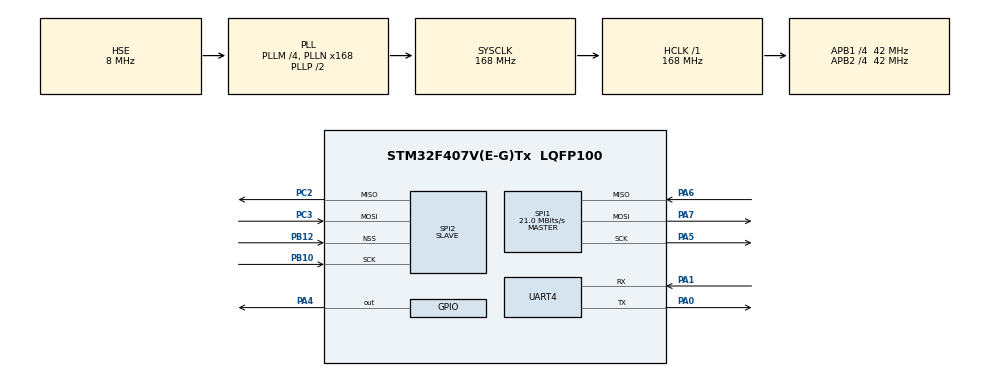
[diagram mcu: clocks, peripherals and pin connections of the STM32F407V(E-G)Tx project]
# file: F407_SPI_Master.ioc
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Mcu.Family=STM32F4
Dma.UART4_RX.0.MemInc=DMA_MINC_ENABLE
PC3.Mode=Full_Duplex_Slave
RCC.PLLSourceVirtual=RCC_PLLSOURCE_HSE
PA6.Mode=Full_Duplex_Master
PH0-OSC_IN.Signal=RCC_OSC_IN
SPI2.VirtualNSS=VM_NSSHARD
Dma.SPI2_RX.1.MemDataAlignment=DMA_MDATAALIGN_BYTE
RCC.CortexFreq_Value=168000000
PA7.Mode=Full_Duplex_Master
SPI1.VirtualType=VM_MASTER
SPI2.VirtualType=VM_SLAVE
PB10.Mode=Full_Duplex_Slave
NVIC.DMA1_Stream2_IRQn=true\:0\:0\:false\:false\:true\:false\:true
Dma.UART4_RX.0.Mode=DMA_CIRCULAR
PC2.Signal=SPI2_MISO
PC2.Mode=Full_Duplex_Slave
RCC.APB1CLKDivider=RCC_HCLK_DIV4
UART4.VirtualMode=Asynchronous
Dma.SPI2_RX.1.Mode=DMA_CIRCULAR
Dma.SPI2_RX.1.Direction=DMA_PERIPH_TO_MEMORY
RCC.SYSCLKSource=RCC_SYSCLKSOURCE_PLLCLK
ProjectManager.StackSize=0x400
PA0-WKUP.Signal=UART4_TX
PA0-WKUP.Mode=Asynchronous
Dma.SPI2_RX.1.PeriphDataAlignment=DMA_PDATAALIGN_BYTE
Dma.UART4_RX.0.Direction=DMA_PERIPH_TO_MEMORY
PA4.PinState=GPIO_PIN_SET
ProjectManager.TargetToolchain=STM32CubeIDE
SPI1.Direction=SPI_DIRECTION_2LINES
RCC.HCLKFreq_Value=168000000
RCC.APB2TimFreq_Value=84000000
SPI1.CalculateBaudRate=21.0 MBits/s
PC3.Signal=SPI2_MOSI
Dma.UART4_RX.0.PeriphInc=DMA_PINC_DISABLE
RCC.LSE_VALUE=32768
PA1.Signal=UART4_RX
RCC.AHBFreq_Value=168000000
PH0-OSC_IN.Mode=HSE-External-Oscillator
PB10.Signal=SPI2_SCK
PA5.Signal=SPI1_SCK
RCC.HSE_VALUE=8000000
board=custom
RCC.VCOOutputFreq_Value=336000000
Dma.UART4_RX.0.MemDataAlignment=DMA_MDATAALIGN_BYTE
Dma.UART4_RX.0.FIFOMode=DMA_FIFOMODE_DISABLE
PA4.GPIO_Speed=GPIO_SPEED_FREQ_VERY_HIGH
Dma.UART4_RX.0.Priority=DMA_PRIORITY_LOW
NVIC.SPI1_IRQn=true\:0\:0\:false\:false\:true\:true\:true
RCC.APB2Freq_Value=42000000
PA1.Mode=Asynchronous
Dma.SPI2_RX.1.FIFOMode=DMA_FIFOMODE_DISABLE
Dma.SPI2_RX.1.Priority=DMA_PRIORITY_LOW
SPI1.Mode=SPI_MODE_MASTER
PH1-OSC_OUT.Signal=RCC_OSC_OUT
NVIC.SPI2_IRQn=true\:0\:0\:false\:false\:true\:true\:true
Dma.UART4_RX.0.PeriphDataAlignment=DMA_PDATAALIGN_BYTE
Mcu.Name=STM32F407V(E-G)Tx
Dma.SPI2_RX.1.PeriphInc=DMA_PINC_DISABLE
PH1-OSC_OUT.Mode=HSE-External-Oscillator
RCC.48MHZClocksFreq_Value=84000000
PA4.Signal=GPIO_Output
RCC.SYSCLKFreq_VALUE=168000000
Mcu.Package=LQFP100
PA6.Signal=SPI1_MISO
PB12.Mode=NSS_Signal_Hard_Input
SPI2.Mode=SPI_MODE_SLAVE
ProjectManager.HeapSize=0x200
Dma.SPI2_RX.1.Instance=DMA1_Stream3
RCC.HSI_VALUE=16000000
NVIC.PriorityGroup=NVIC_PRIORITYGROUP_4
RCC.APB2CLKDivider=RCC_HCLK_DIV4
RCC.PLLM=4
RCC.PLLN=168
Dma.UART4_RX.0.Instance=DMA1_Stream2
Dma.Request1=SPI2_RX
RCC.APB1TimFreq_Value=84000000
NVIC.DMA1_Stream3_IRQn=true\:0\:0\:false\:false\:true\:false\:true
SPI2.Direction=SPI_DIRECTION_2LINES
Dma.Request0=UART4_RX
RCC.APB1Freq_Value=42000000
Dma.SPI2_RX.1.MemInc=DMA_MINC_ENABLE
PB12.Signal=SPI2_NSS
NVIC.UART4_IRQn=true\:0\:0\:false\:false\:true\:true\:true
PA5.Mode=Full_Duplex_Master
PA7.Signal=SPI1_MOSI

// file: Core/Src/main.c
/* USER CODE BEGIN Header */
/**
  ******************************************************************************
  * @file           : main.c
  * @brief          : Main program body
  ******************************************************************************
  * @attention
  *
  * <h2><center>&copy; Copyright (c) 2021 STMicroelectronics.
  * All rights reserved.</center></h2>
  *
  * This software component is licensed by ST under BSD 3-Clause license,
  * the "License"; You may not use this file except in compliance with the
  * License. You may obtain a copy of the License at:
  *                        opensource.org/licenses/BSD-3-Clause
  *
  ******************************************************************************
  */
/* USER CODE END Header */
#include "main.h"
#include <stdio.h>
#include <string.h>

/* USER CODE BEGIN PTD */
#define spi_enable  		HAL_GPIO_WritePin(GPIOA, GPIO_PIN_4, GPIO_PIN_RESET);
#define spi_disable 		HAL_GPIO_WritePin(GPIOA, GPIO_PIN_4, GPIO_PIN_SET);
/* USER CODE END PTD */

SPI_HandleTypeDef hspi1;
SPI_HandleTypeDef hspi2;
DMA_HandleTypeDef hdma_spi2_rx;

UART_HandleTypeDef huart4;
DMA_HandleTypeDef hdma_uart4_rx;

/* USER CODE BEGIN PV */
uint8_t receive_data, send_data;
/* USER CODE END PV */

void SystemClock_Config(void);
static void MX_GPIO_Init(void);
static void MX_DMA_Init(void);
static void MX_UART4_Init(void);
static void MX_SPI1_Init(void);
static void MX_SPI2_Init(void);
/* USER CODE BEGIN PFP */
int __io_putchar (int ch) {
	uint8_t c = ch;
	HAL_UART_Transmit(&huart4, &c, 1, HAL_MAX_DELAY);
	return ch;
}
/* USER CODE END PFP */

int main(void)
{

  /* MCU Configuration--------------------------------------------------------*/

  /* Reset of all peripherals, Initializes the Flash interface and the Systick. */
  HAL_Init();

  /* Configure the system clock */
  SystemClock_Config();

  /* Initialize all configured peripherals */
  MX_GPIO_Init();
  MX_DMA_Init();
  MX_UART4_Init();
  MX_SPI1_Init();
  MX_SPI2_Init();
  /* USER CODE BEGIN 2 */
  //HAL_SPI_Receive_DMA(&hspi2, &receive_data, 1);
  /* USER CODE END 2 */

  /* Infinite loop */
  while (1)
  {
		printf("=====Tran Minh Tan=====\r\n");
		spi_enable;
		HAL_SPI_TransmitReceive_IT(&hspi1, &send_data, &receive_data, 1);
		HAL_Delay(1000);
		send_data++;
  }
}

void HAL_SPI_TxCpltCallback(SPI_HandleTypeDef *hspi)
{
	if(hspi->Instance == hspi1.Instance)
	{
		spi_disable;
	}
}
void SystemClock_Config(void)
{
  RCC_OscInitTypeDef RCC_OscInitStruct = {0};
  RCC_ClkInitTypeDef RCC_ClkInitStruct = {0};

  /** Configure the main internal regulator output voltage
  */
  __HAL_RCC_PWR_CLK_ENABLE();
  __HAL_PWR_VOLTAGESCALING_CONFIG(PWR_REGULATOR_VOLTAGE_SCALE1);
  /** Initializes the RCC Oscillators according to the specified parameters
  * in the RCC_OscInitTypeDef structure.
  */
  RCC_OscInitStruct.OscillatorType = RCC_OSCILLATORTYPE_HSE;
  RCC_OscInitStruct.HSEState = RCC_HSE_ON;
  RCC_OscInitStruct.PLL.PLLState = RCC_PLL_ON;
  RCC_OscInitStruct.PLL.PLLSource = RCC_PLLSOURCE_HSE;
  RCC_OscInitStruct.PLL.PLLM = 4;
  RCC_OscInitStruct.PLL.PLLN = 168;
  RCC_OscInitStruct.PLL.PLLP = RCC_PLLP_DIV2;
  RCC_OscInitStruct.PLL.PLLQ = 4;
  if (HAL_RCC_OscConfig(&RCC_OscInitStruct) != HAL_OK)
  {
    Error_Handler();
  }
  /** Initializes the CPU, AHB and APB buses clocks
  */
  RCC_ClkInitStruct.ClockType = RCC_CLOCKTYPE_HCLK|RCC_CLOCKTYPE_SYSCLK
                              |RCC_CLOCKTYPE_PCLK1|RCC_CLOCKTYPE_PCLK2;
  RCC_ClkInitStruct.SYSCLKSource = RCC_SYSCLKSOURCE_PLLCLK;
  RCC_ClkInitStruct.AHBCLKDivider = RCC_SYSCLK_DIV1;
  RCC_ClkInitStruct.APB1CLKDivider = RCC_HCLK_DIV4;
  RCC_ClkInitStruct.APB2CLKDivider = RCC_HCLK_DIV4;

  if (HAL_RCC_ClockConfig(&RCC_ClkInitStruct, FLASH_LATENCY_5) != HAL_OK)
  {
    Error_Handler();
  }
}

static void MX_SPI1_Init(void)
{

  /* SPI1 parameter configuration*/
  hspi1.Instance = SPI1;
  hspi1.Init.Mode = SPI_MODE_MASTER;
  hspi1.Init.Direction = SPI_DIRECTION_2LINES;
  hspi1.Init.DataSize = SPI_DATASIZE_8BIT;
  hspi1.Init.CLKPolarity = SPI_POLARITY_LOW;
  hspi1.Init.CLKPhase = SPI_PHASE_1EDGE;
  hspi1.Init.NSS = SPI_NSS_SOFT;
  hspi1.Init.BaudRatePrescaler = SPI_BAUDRATEPRESCALER_2;
  hspi1.Init.FirstBit = SPI_FIRSTBIT_MSB;
  hspi1.Init.TIMode = SPI_TIMODE_DISABLE;
  hspi1.Init.CRCCalculation = SPI_CRCCALCULATION_DISABLE;
  hspi1.Init.CRCPolynomial = 10;
  if (HAL_SPI_Init(&hspi1) != HAL_OK)
  {
    Error_Handler();
  }

}

static void MX_SPI2_Init(void)
{

  /* SPI2 parameter configuration*/
  hspi2.Instance = SPI2;
  hspi2.Init.Mode = SPI_MODE_SLAVE;
  hspi2.Init.Direction = SPI_DIRECTION_2LINES;
  hspi2.Init.DataSize = SPI_DATASIZE_8BIT;
  hspi2.Init.CLKPolarity = SPI_POLARITY_LOW;
  hspi2.Init.CLKPhase = SPI_PHASE_1EDGE;
  hspi2.Init.NSS = SPI_NSS_HARD_INPUT;
  hspi2.Init.FirstBit = SPI_FIRSTBIT_MSB;
  hspi2.Init.TIMode = SPI_TIMODE_DISABLE;
  hspi2.Init.CRCCalculation = SPI_CRCCALCULATION_DISABLE;
  hspi2.Init.CRCPolynomial = 10;
  if (HAL_SPI_Init(&hspi2) != HAL_OK)
  {
    Error_Handler();
  }

}

static void MX_UART4_Init(void)
{

  huart4.Instance = UART4;
  huart4.Init.BaudRate = 115200;
  huart4.Init.WordLength = UART_WORDLENGTH_8B;
  huart4.Init.StopBits = UART_STOPBITS_1;
  huart4.Init.Parity = UART_PARITY_NONE;
  huart4.Init.Mode = UART_MODE_TX_RX;
  huart4.Init.HwFlowCtl = UART_HWCONTROL_NONE;
  huart4.Init.OverSampling = UART_OVERSAMPLING_16;
  if (HAL_UART_Init(&huart4) != HAL_OK)
  {
    Error_Handler();
  }

}

static void MX_DMA_Init(void)
{

  /* DMA controller clock enable */
  __HAL_RCC_DMA1_CLK_ENABLE();

  /* DMA interrupt init */
  /* DMA1_Stream2_IRQn interrupt configuration */
  HAL_NVIC_SetPriority(DMA1_Stream2_IRQn, 0, 0);
  HAL_NVIC_EnableIRQ(DMA1_Stream2_IRQn);
  /* DMA1_Stream3_IRQn interrupt configuration */
  HAL_NVIC_SetPriority(DMA1_Stream3_IRQn, 0, 0);
  HAL_NVIC_EnableIRQ(DMA1_Stream3_IRQn);

}

static void MX_GPIO_Init(void)
{
  GPIO_InitTypeDef GPIO_InitStruct = {0};

  /* GPIO Ports Clock Enable */
  __HAL_RCC_GPIOH_CLK_ENABLE();
  __HAL_RCC_GPIOC_CLK_ENABLE();
  __HAL_RCC_GPIOA_CLK_ENABLE();
  __HAL_RCC_GPIOB_CLK_ENABLE();

  /*Configure GPIO pin Output Level */
  HAL_GPIO_WritePin(GPIOA, GPIO_PIN_4, GPIO_PIN_SET);

  /*Configure GPIO pin : PA4 */
  GPIO_InitStruct.Pin = GPIO_PIN_4;
  GPIO_InitStruct.Mode = GPIO_MODE_OUTPUT_PP;
  GPIO_InitStruct.Pull = GPIO_NOPULL;
  GPIO_InitStruct.Speed = GPIO_SPEED_FREQ_VERY_HIGH;
  HAL_GPIO_Init(GPIOA, &GPIO_InitStruct);

}

void Error_Handler(void)
{
}

/************************ (C) COPYRIGHT STMicroelectronics *****END OF FILE****/
